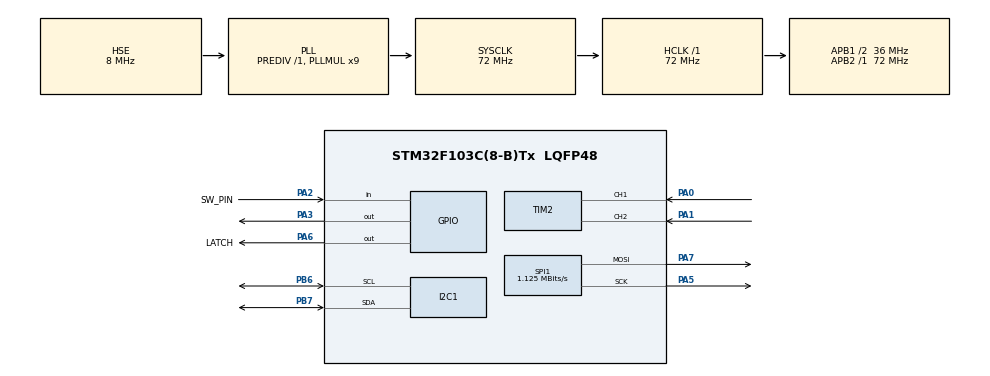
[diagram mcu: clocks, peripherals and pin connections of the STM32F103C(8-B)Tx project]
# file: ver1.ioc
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Mcu.Family=STM32F1
Mcu.Name=STM32F103C(8-B)Tx
Mcu.Package=LQFP48
NVIC.PriorityGroup=NVIC_PRIORITYGROUP_4
NVIC.TIM2_IRQn=true\:0\:0\:false\:false\:true\:true\:true\:true
PA0-WKUP.Signal=S_TIM2_CH1_ETR
PA1.Signal=S_TIM2_CH2
PA13.Mode=Serial_Wire
PA13.Signal=SYS_JTMS-SWDIO
PA14.Mode=Serial_Wire
PA14.Signal=SYS_JTCK-SWCLK
PA2.GPIO_Label=SW_PIN
PA2.GPIO_PuPd=GPIO_PULLUP
PA2.Signal=GPIO_Input
PA3.Signal=GPIO_Output
PA5.Mode=TX_Only_Simplex_Unidirect_Master
PA5.Signal=SPI1_SCK
PA6.GPIO_Label=LATCH
PA6.Signal=GPIO_Output
PA7.Mode=TX_Only_Simplex_Unidirect_Master
PA7.Signal=SPI1_MOSI
PB6.Mode=I2C
PB6.Signal=I2C1_SCL
PB7.Mode=I2C
PB7.Signal=I2C1_SDA
PD0-OSC_IN.Mode=HSE-External-Oscillator
PD0-OSC_IN.Signal=RCC_OSC_IN
PD1-OSC_OUT.Mode=HSE-External-Oscillator
PD1-OSC_OUT.Signal=RCC_OSC_OUT
ProjectManager.HeapSize=0x200
ProjectManager.StackSize=0x400
ProjectManager.TargetToolchain=STM32CubeIDE
RCC.AHBFreq_Value=72000000
RCC.APB1CLKDivider=RCC_HCLK_DIV2
RCC.APB1Freq_Value=36000000
RCC.APB1TimFreq_Value=72000000
RCC.APB2Freq_Value=72000000
RCC.APB2TimFreq_Value=72000000
RCC.HCLKFreq_Value=72000000
RCC.PLLMUL=RCC_PLL_MUL9
RCC.PLLSourceVirtual=RCC_PLLSOURCE_HSE
RCC.SYSCLKFreq_VALUE=72000000
RCC.SYSCLKSource=RCC_SYSCLKSOURCE_PLLCLK
RCC.USBFreq_Value=72000000
SH.S_TIM2_CH1_ETR.0=TIM2_CH1,Encoder_Interface
SH.S_TIM2_CH2.0=TIM2_CH2,Encoder_Interface
SPI1.BaudRatePrescaler=SPI_BAUDRATEPRESCALER_64
SPI1.CalculateBaudRate=1.125 MBits/s
SPI1.Direction=SPI_DIRECTION_2LINES
SPI1.Mode=SPI_MODE_MASTER
SPI1.VirtualType=VM_MASTER
TIM2.AutoReloadPreload=TIM_AUTORELOAD_PRELOAD_ENABLE
TIM2.EncoderMode=TIM_ENCODERMODE_TI12
TIM2.IC1Filter=10
TIM2.IC2Filter=10
board=custom

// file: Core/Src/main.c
/* USER CODE BEGIN Header */
/**
  ******************************************************************************
  * @file           : main.c
  * @brief          : Main program body
  ******************************************************************************
  * @attention
  *
  * Copyright (c) 2023 STMicroelectronics.
  * All rights reserved.
  *
  * This software is licensed under terms that can be found in the LICENSE file
  * in the root directory of this software component.
  * If no LICENSE file comes with this software, it is provided AS-IS.
  *
  ******************************************************************************
  */
/* USER CODE END Header */
#include "main.h"

/* USER CODE BEGIN Includes */
#include <stdio.h>
#include "button.h"
#include "Rotary_Encoder.h"
#include "Display.h"

/* USER CODE END Includes */

I2C_HandleTypeDef hi2c1;

SPI_HandleTypeDef hspi1;

TIM_HandleTypeDef htim2;

/* USER CODE BEGIN PV */
BUTTON_HandleTypeDef encoder_button;
BUTTON_StatusTypeDef button_status = BUTTON_RELEASING;
RE_HandleTypeDef rotary_encoder;
DS3231_HandleTypeDef ds3231;
//extern time_component_t time_component;
int count = 0;
/* USER CODE END PV */

void SystemClock_Config(void);
static void MX_GPIO_Init(void);
static void MX_I2C1_Init(void);
static void MX_SPI1_Init(void);
static void MX_TIM2_Init(void);

/* USER CODE BEGIN 0 */
//void HAL_TIM_PeriodElapsedCallback(TIM_HandleTypeDef *htim)
//{
//    if (htim->Instance == htim3.Instance){
//        if (time_component == 2) time_component = 0;
//        else time_component++;
//    }
//}

/* USER CODE END 0 */

int main(void)
{

  /* MCU Configuration--------------------------------------------------------*/

  /* Reset of all peripherals, Initializes the Flash interface and the Systick. */
  HAL_Init();

  /* Configure the system clock */
  SystemClock_Config();

  /* Initialize all configured peripherals */
  MX_GPIO_Init();
  MX_I2C1_Init();
  MX_SPI1_Init();
  MX_TIM2_Init();
  /* USER CODE BEGIN 2 */
//  BUTTON_Init(&encoder_button, GPIOA, GPIO_PIN_2);
  RE_Init(&rotary_encoder, &htim2);
  DS3231_Init(&ds3231, &hi2c1);
//  DS3231_Set_Time(&ds3231, 30, 0, 22, 3, 14, 03, 23);
  /* USER CODE END 2 */

  /* Infinite loop */
  while (1)
  {

    /* USER CODE BEGIN 3 */
//	  BUTTON_Handle(&encoder_button);
	  RE_Handle(&rotary_encoder);
//	  Display_LED(&hspi1, &ds3231);
	  DS3231_Get_Time(&ds3231);
  }
  /* USER CODE END 3 */
}

void SystemClock_Config(void)
{
  RCC_OscInitTypeDef RCC_OscInitStruct = {0};
  RCC_ClkInitTypeDef RCC_ClkInitStruct = {0};

  /** Initializes the RCC Oscillators according to the specified parameters
  * in the RCC_OscInitTypeDef structure.
  */
  RCC_OscInitStruct.OscillatorType = RCC_OSCILLATORTYPE_HSE;
  RCC_OscInitStruct.HSEState = RCC_HSE_ON;
  RCC_OscInitStruct.HSEPredivValue = RCC_HSE_PREDIV_DIV1;
  RCC_OscInitStruct.HSIState = RCC_HSI_ON;
  RCC_OscInitStruct.PLL.PLLState = RCC_PLL_ON;
  RCC_OscInitStruct.PLL.PLLSource = RCC_PLLSOURCE_HSE;
  RCC_OscInitStruct.PLL.PLLMUL = RCC_PLL_MUL9;
  if (HAL_RCC_OscConfig(&RCC_OscInitStruct) != HAL_OK)
  {
    Error_Handler();
  }

  /** Initializes the CPU, AHB and APB buses clocks
  */
  RCC_ClkInitStruct.ClockType = RCC_CLOCKTYPE_HCLK|RCC_CLOCKTYPE_SYSCLK
                              |RCC_CLOCKTYPE_PCLK1|RCC_CLOCKTYPE_PCLK2;
  RCC_ClkInitStruct.SYSCLKSource = RCC_SYSCLKSOURCE_PLLCLK;
  RCC_ClkInitStruct.AHBCLKDivider = RCC_SYSCLK_DIV1;
  RCC_ClkInitStruct.APB1CLKDivider = RCC_HCLK_DIV2;
  RCC_ClkInitStruct.APB2CLKDivider = RCC_HCLK_DIV1;

  if (HAL_RCC_ClockConfig(&RCC_ClkInitStruct, FLASH_LATENCY_2) != HAL_OK)
  {
    Error_Handler();
  }
}

static void MX_I2C1_Init(void)
{

  hi2c1.Instance = I2C1;
  hi2c1.Init.ClockSpeed = 100000;
  hi2c1.Init.DutyCycle = I2C_DUTYCYCLE_2;
  hi2c1.Init.OwnAddress1 = 0;
  hi2c1.Init.AddressingMode = I2C_ADDRESSINGMODE_7BIT;
  hi2c1.Init.DualAddressMode = I2C_DUALADDRESS_DISABLE;
  hi2c1.Init.OwnAddress2 = 0;
  hi2c1.Init.GeneralCallMode = I2C_GENERALCALL_DISABLE;
  hi2c1.Init.NoStretchMode = I2C_NOSTRETCH_DISABLE;
  if (HAL_I2C_Init(&hi2c1) != HAL_OK)
  {
    Error_Handler();
  }

}

static void MX_SPI1_Init(void)
{

  /* SPI1 parameter configuration*/
  hspi1.Instance = SPI1;
  hspi1.Init.Mode = SPI_MODE_MASTER;
  hspi1.Init.Direction = SPI_DIRECTION_2LINES;
  hspi1.Init.DataSize = SPI_DATASIZE_8BIT;
  hspi1.Init.CLKPolarity = SPI_POLARITY_LOW;
  hspi1.Init.CLKPhase = SPI_PHASE_1EDGE;
  hspi1.Init.NSS = SPI_NSS_SOFT;
  hspi1.Init.BaudRatePrescaler = SPI_BAUDRATEPRESCALER_64;
  hspi1.Init.FirstBit = SPI_FIRSTBIT_MSB;
  hspi1.Init.TIMode = SPI_TIMODE_DISABLE;
  hspi1.Init.CRCCalculation = SPI_CRCCALCULATION_DISABLE;
  hspi1.Init.CRCPolynomial = 10;
  if (HAL_SPI_Init(&hspi1) != HAL_OK)
  {
    Error_Handler();
  }

}

static void MX_TIM2_Init(void)
{

  TIM_Encoder_InitTypeDef sConfig = {0};
  TIM_MasterConfigTypeDef sMasterConfig = {0};

  htim2.Instance = TIM2;
  htim2.Init.Prescaler = 0;
  htim2.Init.CounterMode = TIM_COUNTERMODE_UP;
  htim2.Init.Period = 65535;
  htim2.Init.ClockDivision = TIM_CLOCKDIVISION_DIV1;
  htim2.Init.AutoReloadPreload = TIM_AUTORELOAD_PRELOAD_ENABLE;
  sConfig.EncoderMode = TIM_ENCODERMODE_TI12;
  sConfig.IC1Polarity = TIM_ICPOLARITY_RISING;
  sConfig.IC1Selection = TIM_ICSELECTION_DIRECTTI;
  sConfig.IC1Prescaler = TIM_ICPSC_DIV1;
  sConfig.IC1Filter = 10;
  sConfig.IC2Polarity = TIM_ICPOLARITY_RISING;
  sConfig.IC2Selection = TIM_ICSELECTION_DIRECTTI;
  sConfig.IC2Prescaler = TIM_ICPSC_DIV1;
  sConfig.IC2Filter = 10;
  if (HAL_TIM_Encoder_Init(&htim2, &sConfig) != HAL_OK)
  {
    Error_Handler();
  }
  sMasterConfig.MasterOutputTrigger = TIM_TRGO_RESET;
  sMasterConfig.MasterSlaveMode = TIM_MASTERSLAVEMODE_DISABLE;
  if (HAL_TIMEx_MasterConfigSynchronization(&htim2, &sMasterConfig) != HAL_OK)
  {
    Error_Handler();
  }

}

static void MX_GPIO_Init(void)
{
  GPIO_InitTypeDef GPIO_InitStruct = {0};

  /* GPIO Ports Clock Enable */
  __HAL_RCC_GPIOD_CLK_ENABLE();
  __HAL_RCC_GPIOA_CLK_ENABLE();
  __HAL_RCC_GPIOB_CLK_ENABLE();

  /*Configure GPIO pin Output Level */
  HAL_GPIO_WritePin(GPIOA, GPIO_PIN_3|LATCH_Pin, GPIO_PIN_RESET);

  /*Configure GPIO pin : SW_PIN_Pin */
  GPIO_InitStruct.Pin = SW_PIN_Pin;
  GPIO_InitStruct.Mode = GPIO_MODE_INPUT;
  GPIO_InitStruct.Pull = GPIO_PULLUP;
  HAL_GPIO_Init(SW_PIN_GPIO_Port, &GPIO_InitStruct);

  /*Configure GPIO pins : PA3 LATCH_Pin */
  GPIO_InitStruct.Pin = GPIO_PIN_3|LATCH_Pin;
  GPIO_InitStruct.Mode = GPIO_MODE_OUTPUT_PP;
  GPIO_InitStruct.Pull = GPIO_NOPULL;
  GPIO_InitStruct.Speed = GPIO_SPEED_FREQ_LOW;
  HAL_GPIO_Init(GPIOA, &GPIO_InitStruct);

}

void Error_Handler(void)
{
  __disable_irq();
  while (1)
  {
  }
}
